# STM32G071xx register map
File version: 1.0
Registers are 32-bit, read-write, reset 0x0 unless marked. A register's access mark holds for its fields unless they carry their own. Offsets are from the block's base; [hi:lo] are bit positions; {n}, {i} and the like mark numbered series; 'fields as' and 'values as' point back to an identical list.

## COMP12_COMMON
Base 0x40010200; alternate view of COMP1
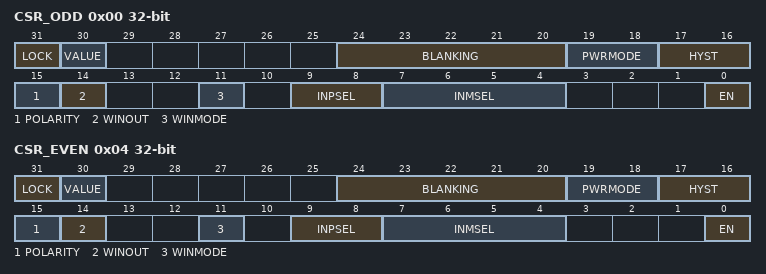
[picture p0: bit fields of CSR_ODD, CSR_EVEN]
0x00 CSR_ODD — COMP control and status register located in register of comparator instance odd, used for bits common to several COMP instances
  [31] LOCK — Comparator lock
  [30] VALUE — Comparator output level
  [24:20] BLANKING — Comparator blanking source
    0=NONE (Comparator output without blanking); 1=TIM1_OC4 (Comparator output blanking source TIM1 OC4 (common to all COMP instances: COMP1, COMP2, COMP3 (when available))); 2=TIM1_OC5 (Comparator output blanking source TIM1 OC5 (common to all COMP instances: COMP1, COMP2, COMP3 (when available))); 4=TIM2_OC3 (Comparator output blanking source TIM2 OC3 (common to all COMP instances: COMP1, COMP2, COMP3 (when available))); 8=TIM3_OC3 (Comparator output blanking source TIM3 OC3 (common to all COMP instances: COMP1, COMP2, COMP3 (when available))); 16=TIM15_OC2 (Comparator output blanking source TIM15 OC2 (common to all COMP instances: COMP1, COMP2, COMP3 (when available)))
  [19:18] PWRMODE — Comparator power mode
    0=HIGHSPEED (COMP power mode to high speed); 1=MEDIUMSPEED (COMP power mode to medium speed)
  [17:16] HYST — Comparator input hysteresis
    0=NONE (No hysteresis); 1=LOW (Hysteresis level low); 2=MEDIUM (Hysteresis level medium); 3=HIGH (Hysteresis level high)
  [15] POLARITY — Comparator output polarity
    0=NONINVERTED (COMP output polarity is not inverted: comparator output is high when the plus (non-inverting) input is at a higher voltage than the minus (inverting) input); 1=INVERTED (COMP output polarity is inverted: comparator output is low when the plus (non-inverting) input is at a lower voltage than the minus (inverting) input)
  [14] WINOUT — Pair of comparators window output level. Bit intended to be used with COMP common instance (COMP_Common_TypeDef)
  [11] WINMODE — Pair of comparators window mode. Bit intended to be used with COMP common instance (COMP_Common_TypeDef)
  [9:8] INPSEL — Comparator plus minus selection
    0=IO1 (Comparator input plus connected to IO1 (pin PC5 for COMP1, pin PB4 for COMP2, pin PB0 for COMP3 (for devices featuring COMP3 instance))); 1=IO2 (Comparator input plus connected to IO2 (pin PB2 for COMP1, pin PB6 for COMP2, pin PC1 for COMP3 (for devices featuring COMP3 instance))); 2=IO3 (Comparator input plus connected to IO3 (pin PA1 for COMP1, pin PA3 for COMP2, pin PE7 for COMP3 (for devices featuring COMP3 instance)))
  [7:4] INMSEL — Comparator input minus selection
    0=MINUS_1_4VREFINT (Comparator input minus connected to 1/4 VrefInt); 1=MINUS_1_2VREFINT (Comparator input minus connected to 1/2 VrefInt); 2=MINUS_3_4VREFINT (Comparator input minus connected to 3/4 VrefInt); 3=VREFINT (Comparator input minus connected to VrefInt); 4=DAC1_CH1 (Comparator input minus connected to DAC1 channel 1 (DAC_OUT1)); 5=DAC1_CH2 (Comparator input minus connected to DAC1 channel 2 (DAC_OUT2)); 6=IO1 (Comparator input minus connected to IO1 (pin PB1 for COMP1, pin PB3 for COMP2, pin PB2 for COMP3 (for devices featuring COMP3 instance))); 7=IO2 (Comparator input minus connected to IO2 (pin PC4 for COMP1, pin PB7 for COMP2, pin PC0 for COMP3 (for devices featuring COMP3 instance))); 8=IO3 (Comparator input minus connected to IO3 (pin PA0 for COMP1, pin PA2 for COMP2, pin PE8 for COMP3 (for devices featuring COMP3 instance)))
  [0] EN — Comparator enable
0x04 CSR_EVEN — COMP control and status register located in register of comparator instance even, used for bits common to several COMP instances
  fields as CSR_ODD

## DBG — Debug MCU
Base 0x40015800
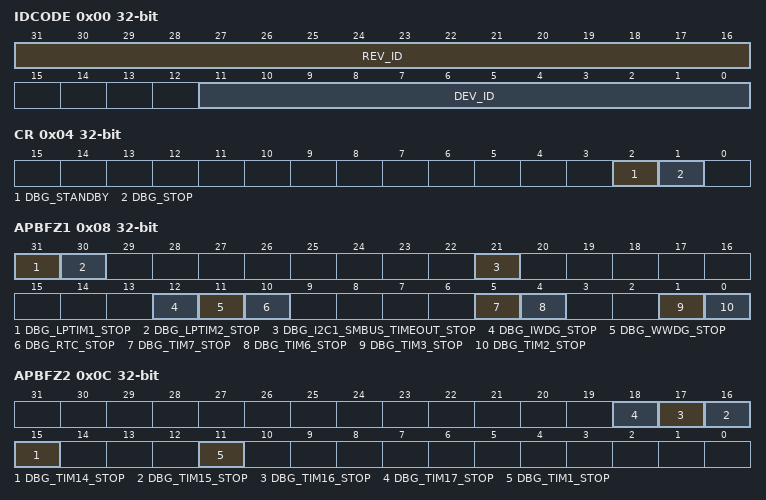
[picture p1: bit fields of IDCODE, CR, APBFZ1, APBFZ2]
0x00 IDCODE — MCU device ID code
  [31:16] REV_ID, [11:0] DEV_ID
0x04 CR — Debug configuration register
  [2] DBG_STANDBY, [1] DBG_STOP
0x08 APBFZ1 — Debug APB freeze register 1
  [31] DBG_LPTIM1_STOP, [30] DBG_LPTIM2_STOP, [21] DBG_I2C1_SMBUS_TIMEOUT_STOP, [12] DBG_IWDG_STOP, [11] DBG_WWDG_STOP, [10] DBG_RTC_STOP, [5] DBG_TIM7_STOP, [4] DBG_TIM6_STOP, [1] DBG_TIM3_STOP, [0] DBG_TIM2_STOP
0x0C APBFZ2 — Debug APB freeze register 2
  [n+1] DBG_TIM{n}_STOP (n=14..17), [11] DBG_TIM1_STOP
